# GT32U2086 register map
Vendor: FPTTelecom
Registers are 32-bit, read-write, reset 0x0 unless marked. A register's access mark holds for its fields unless they carry their own. Offsets are from the block's base; [hi:lo] are bit positions; {n}, {i} and the like mark numbered series; 'fields as' and 'values as' point back to an identical list.

## TIM0 — TIM0 - TIMER TIM0 : 0x44060000 - 0x4406FFFF (64 KB) Reference: dti_timer_ug_rev1p0.pdf
Base 0x44060000
Same registers: TIM1 0x44070000, TIM2 0x44080000, TIM3 0x44090000, TIM4 0x500B0000, TIM5 0x500C0000, TIM6 0x500D0000, TIM7 0x500E0000
0x00 CNT_CH0 ro — Counter Value Register - Channel 0 bit[31:0] CNT_VALUE
  [31:0] CNT_VALUE — 32-bit counter value for channel 0
0x04 CNT_CH1 ro — Counter Value Register - Channel 1 bit[31:0] CNT_VALUE
  [31:0] CNT_VALUE — 32-bit counter value for channel 1
0x08 PRSC_CH0 — Prescaler Register - Channel 0 bit[31:0] PRESCALER
  [31:0] PRESCALER — 32-bit prescaler value for channel 0
0x0C PRSC_CH1 — Prescaler Register - Channel 1 bit[31:0] PRESCALER
  [31:0] PRESCALER — 32-bit prescaler value for channel 1
0x10 CHL_CH0 — Counter Hot Reload Register - Channel 0 bit[31:0] RELOAD_VALUE
  [31:0] HOT_RELOAD — 32-bit counter hot-reload value for channel 0
0x14 CHL_CH1 — Counter Hot Reload Register - Channel 1 bit[31:0] RELOAD_VALUE
  [31:0] HOT_RELOAD — 32-bit counter hot-reload value for channel 1
{0x10+8i} CCR{i}_CH0 reset 0xFFFFFFFF (i=1..4) — Capture/Compare Register {i} - Channel 0 bit[31:0] CC_VALUE
  [31:0] CC_VALUE — Capture/compare value {i} for channel 0
{0x14+8i} CCR{i}_CH1 reset 0xFFFFFFFF (i=1..4) — Capture/Compare Register {i} - Channel 1 bit[31:0] CC_VALUE
  [31:0] CC_VALUE — Capture/compare value {i} for channel 1
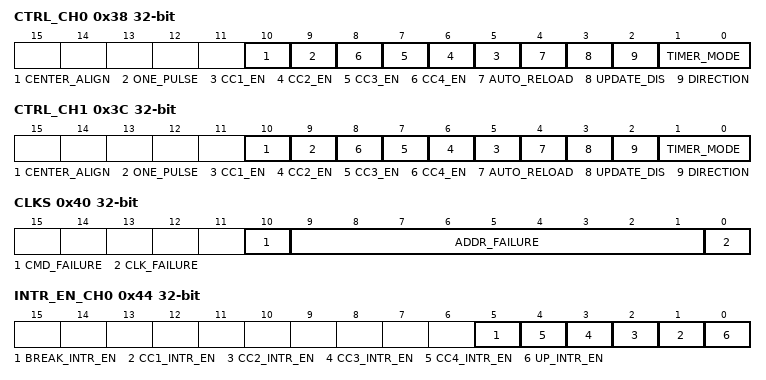
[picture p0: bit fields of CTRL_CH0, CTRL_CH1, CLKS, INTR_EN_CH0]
0x38 CTRL_CH0 — Timer Control Register - Channel 0 bit[1:0] TIMER_MODE | bit[2] DIRECTION | bit[3] UPDATE_DIS | bit[4] AUTO_RELOAD | bit[5] CC1_EN | bit[6] CC2_EN | bit[7] CC3_EN | bit[8] CC4_EN | bit[9] ONE_PULSE | bit[10] CENTER_ALIGN
  [10] CENTER_ALIGN — Enable center-aligned counting mode
  [9] ONE_PULSE — Enable one-pulse mode
  [n+4] CC{n}_EN (n=1..4) — Enable capture/compare {n}
  [4] AUTO_RELOAD — Enable preload of the auto-reload value
  [3] UPDATE_DIS — Disable update events when set to 1
  [2] DIRECTION — Count direction: 0=count up, 1=count down
  [1:0] TIMER_MODE — Timer mode: 0=disabled, 1=normal counting, 2=PWM0, 3=PWM1
0x3C CTRL_CH1 — Timer Control Register - Channel 1 bit[1:0] TIMER_MODE | bit[2] DIRECTION | bit[3] UPDATE_DIS | bit[4] AUTO_RELOAD | bit[5] CC1_EN | bit[6] CC2_EN | bit[7] CC3_EN | bit[8] CC4_EN | bit[9] ONE_PULSE | bit[10] CENTER_ALIGN
  fields as CTRL_CH0
0x40 CLKS ro — Clock Status Register bit[0] CLK_FAILURE | bit[9:1] ADDR_FAILURE | bit[10] CMD_FAILURE; read-to-clear
  [10] CMD_FAILURE — First failed command type: 0=write, 1=read
  [9:1] ADDR_FAILURE — Faulting address, bit field [9:1]
  [0] CLK_FAILURE — Clock-failure detection flag
0x44 INTR_EN_CH0 — Interrupt Control Register - Channel 0 bit[0] UP_INTR_EN | bit[1] CC1_INTR_EN | bit[2] CC2_INTR_EN | bit[3] CC3_INTR_EN | bit[4] CC4_INTR_EN | bit[5] BREAK_INTR_EN
  [5] BREAK_INTR_EN — Enable break-event interrupt
  [n] CC{n}_INTR_EN (n=1..4) — Enable capture/compare interrupt {n}
  [0] UP_INTR_EN — Enable update-event interrupt
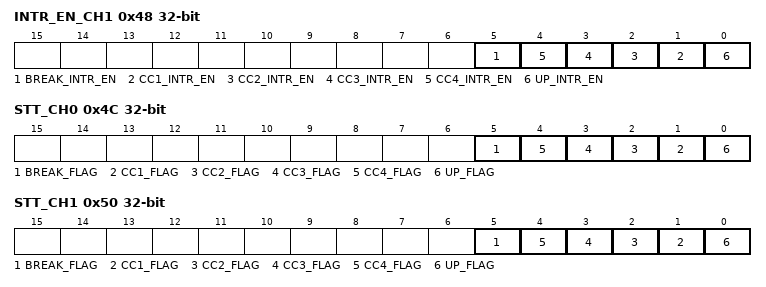
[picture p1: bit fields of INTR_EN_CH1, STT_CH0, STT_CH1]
0x48 INTR_EN_CH1 — Interrupt Control Register - Channel 1 bit[0] UP_INTR_EN | bit[1] CC1_INTR_EN | bit[2] CC2_INTR_EN | bit[3] CC3_INTR_EN | bit[4] CC4_INTR_EN | bit[5] BREAK_INTR_EN
  fields as INTR_EN_CH0
0x4C STT_CH0 ro — Status Register - Channel 0 bit[0] UP_FLAG | bit[1] CC1_FLAG | bit[2] CC2_FLAG | bit[3] CC3_FLAG | bit[4] CC4_FLAG | bit[5] BREAK_FLAG; FPGA read-only live event levels, not latched; reading does not clear flags or IRQ (UG labels register RW)
  [5] BREAK_FLAG — Break-event flag
  [n] CC{n}_FLAG (n=1..4) — Capture/compare event flag {n}
  [0] UP_FLAG — Update-event flag
0x50 STT_CH1 ro — Status Register - Channel 1 bit[0] UP_FLAG | bit[1] CC1_FLAG | bit[2] CC2_FLAG | bit[3] CC3_FLAG | bit[4] CC4_FLAG | bit[5] BREAK_FLAG; FPGA read-only live event levels, not latched; reading does not clear flags or IRQ (UG labels register RW)
  fields as STT_CH0

## PWM0 — PWM0 - GT32U2086 v8 DTI two-channel PWM register map.
Base 0x440A0000
Registers as TIM0; these are added or differ:
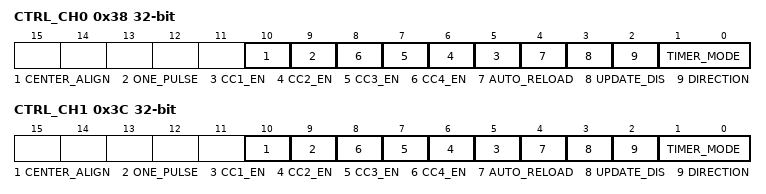
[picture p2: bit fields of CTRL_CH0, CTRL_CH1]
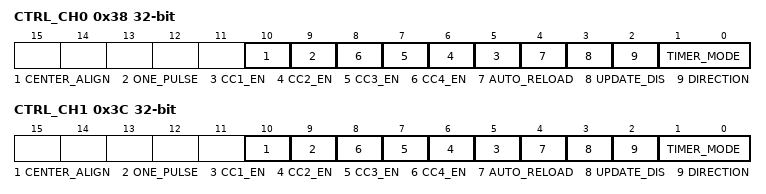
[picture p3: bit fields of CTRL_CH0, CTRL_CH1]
0x38 CTRL_CH0 — Timer Control Register - Channel 0 bit[1:0] TIMER_MODE | bit[2] DIRECTION | bit[3] UPDATE_DIS | bit[4] AUTO_RELOAD | bit[5] CC1_EN | bit[6] CC2_EN | bit[7] CC3_EN | bit[8] CC4_EN | bit[9] ONE_PULSE | bit[10] CENTER_ALIGN
  fields as TIM0.CTRL_CH0
0x3C CTRL_CH1 — Timer Control Register - Channel 1 bit[1:0] TIMER_MODE | bit[2] DIRECTION | bit[3] UPDATE_DIS | bit[4] AUTO_RELOAD | bit[5] CC1_EN | bit[6] CC2_EN | bit[7] CC3_EN | bit[8] CC4_EN | bit[9] ONE_PULSE | bit[10] CENTER_ALIGN
  fields as TIM0.CTRL_CH0

## PWM1 — PWM1 - GT32U2086 v8 DTI two-channel PWM register map.
Base 0x440B0000
Registers as TIM0; these are added or differ:
0x38 CTRL_CH0 — Timer Control Register - Channel 0 bit[1:0] TIMER_MODE | bit[2] DIRECTION | bit[3] UPDATE_DIS | bit[4] AUTO_RELOAD | bit[5] CC1_EN | bit[6] CC2_EN | bit[7] CC3_EN | bit[8] CC4_EN | bit[9] ONE_PULSE | bit[10] CENTER_ALIGN
  fields as TIM0.CTRL_CH0
0x3C CTRL_CH1 — Timer Control Register - Channel 1 bit[1:0] TIMER_MODE | bit[2] DIRECTION | bit[3] UPDATE_DIS | bit[4] AUTO_RELOAD | bit[5] CC1_EN | bit[6] CC2_EN | bit[7] CC3_EN | bit[8] CC4_EN | bit[9] ONE_PULSE | bit[10] CENTER_ALIGN
  fields as TIM0.CTRL_CH0
